# lpgcr_me18 register map
Registers are access not given, no defined reset value unless marked. A register's access mark holds for its fields unless they carry their own. Offsets are from the block's base; lines under a group give offsets from that group; [hi:lo] are bit positions; {n}, {i} and the like mark numbered series; 'fields as' and 'values as' point back to an identical list; <NAME> marks a mode.

## Memory map
0x40080000 LPGCR size 0x400 — Low Power Global Control.

## LPGCR — Low Power Global Control.
Base 0x40080000
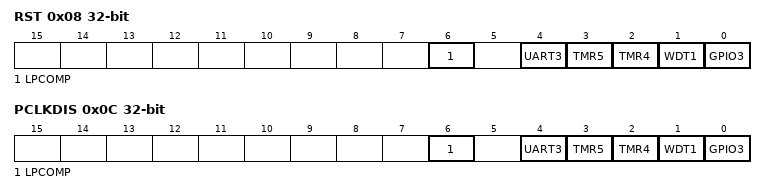
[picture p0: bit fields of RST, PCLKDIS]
0x08 RST — Low Power Reset Register.
  [all] fields
    0=reset_done (Reset complete.); 1=busy (Starts Reset or indicates reset in progress.)
  [6] LPCOMP — Low Power Comparator Reset.
  [4] UART3 — Low Power UART 3 Reset.
  [3] TMR5 — Low Power Timer 5 Reset.
  [2] TMR4 — Low Power Timer 4 Reset.
  [1] WDT1 — Low Power Watchdog Timer 1 Reset.
  [0] GPIO3 — Low Power GPIO 3 Reset.
0x0C PCLKDIS — Low Power Peripheral Clock Disable Register.
  [all] fields
    0=en (enable it.); 1=dis (disable it.)
  [6] LPCOMP — Low Power Comparator Clock Disable.
  [4] UART3 — Low Power UART 3 Clock Disable.
  [3] TMR5 — Low Power Timer 5 Clock Disable.
  [2] TMR4 — Low Power Timer 4 Clock Disable.
  [1] WDT1 — Low Power Watchdog 1 Clock Disable.
  [0] GPIO3 — Low Power GPIO 3 Clock Disable.
